VERSION ""

NS_ :

BS_:

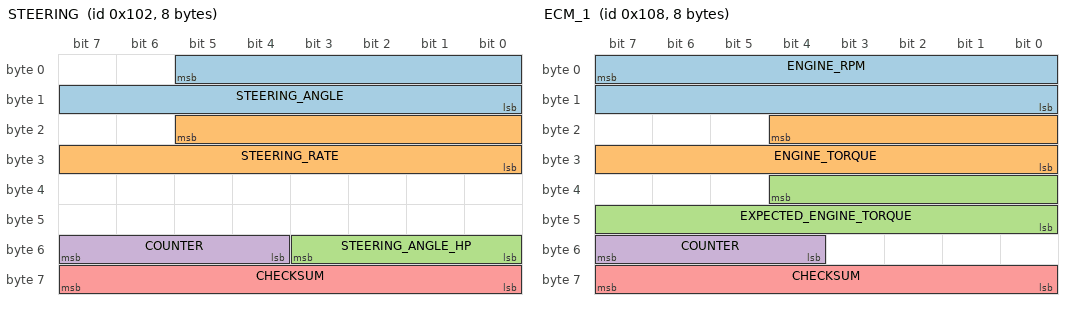
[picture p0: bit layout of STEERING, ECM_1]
BO_ 258 STEERING: 8 XXX
 SG_ STEERING_ANGLE : 5|14@0+ (0.5,-2048) [-2048|2047] "deg" XXX
 SG_ STEERING_RATE : 21|14@0+ (0.5,-2048) [-2048|2047] "deg/s" XXX
 SG_ STEERING_ANGLE_HP : 48|4@1+ (0.1,-0.4) [-0.4|0.4] "deg" XXX
 SG_ COUNTER : 55|4@0+ (1,0) [0|15] "" XXX
 SG_ CHECKSUM : 63|8@0+ (1,0) [0|255] "" XXX

BO_ 264 ECM_1: 8 XXX
 SG_ ENGINE_RPM : 7|16@0+ (1,0) [0|65535] "" XXX
 SG_ ENGINE_TORQUE : 20|13@0+ (0.25,-500) [-500|1547.5] "Nm" XXX
 SG_ EXPECTED_ENGINE_TORQUE : 36|13@0+ (0.25,-500) [-500|1547.5] "Nm" XXX
 SG_ COUNTER : 55|4@0+ (1,0) [0|15] "" XXX
 SG_ CHECKSUM : 63|8@0+ (1,0) [0|255] "" XXX

BO_ 280 ECM_TRQ: 8 XXX
 SG_ ENGINE_TORQ_MAX : 4|13@0+ (.25,-500) [-500|1547.5] "NM" XXX
 SG_ ENGINE_TORQ_MIN : 20|13@0+ (.25,-500) [-500|1547.5] "NM" XXX

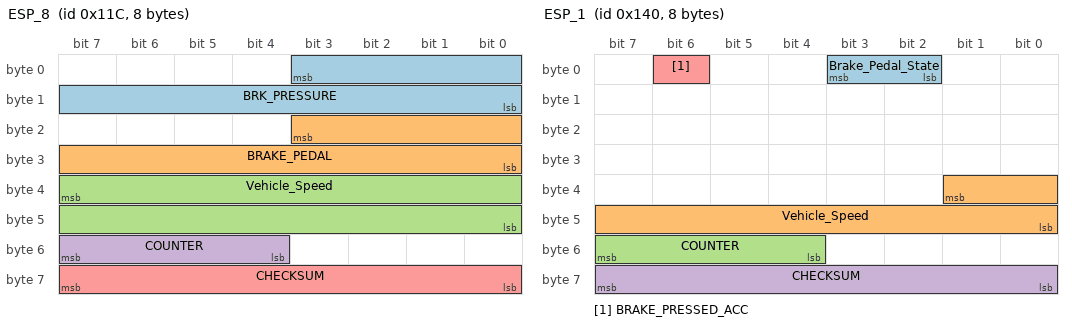
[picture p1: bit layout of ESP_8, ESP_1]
BO_ 284 ESP_8: 8 XXX
 SG_ BRK_PRESSURE : 3|12@0+ (1,0) [0|1] "" XXX
 SG_ BRAKE_PEDAL : 19|12@0+ (1,0) [0|1] "" XXX
 SG_ Vehicle_Speed : 39|16@0+ (0.0078125,0) [0|511.984375] "km/h" XXX
 SG_ COUNTER : 55|4@0+ (1,0) [0|15] "" XXX
 SG_ CHECKSUM : 63|8@0+ (1,0) [0|255] "" XXX

BO_ 320 ESP_1: 8 XXX
 SG_ Brake_Pedal_State : 2|2@1+ (1,0) [0|0] "" XXX
 SG_ Vehicle_Speed : 33|10@0+ (0.5,0) [0|511] "km/h" XXX
 SG_ COUNTER : 55|4@0+ (1,0) [0|15] "" XXX
 SG_ CHECKSUM : 63|8@0+ (1,0) [0|255] "" XXX
 SG_ BRAKE_PRESSED_ACC : 6|1@0+ (1,0) [0|3] "" XXX

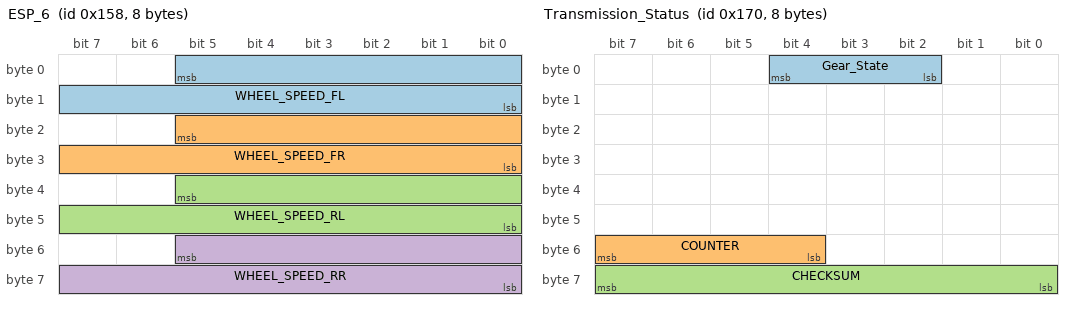
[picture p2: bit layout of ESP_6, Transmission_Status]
BO_ 344 ESP_6: 8 XXX
 SG_ WHEEL_SPEED_FL : 5|14@0+ (0.5,0) [0|8191] "rpm" XXX
 SG_ WHEEL_SPEED_FR : 21|14@0+ (0.5,0) [0|8191] "rpm" XXX
 SG_ WHEEL_SPEED_RL : 37|14@0+ (0.5,0) [0|8191] "rpm" XXX
 SG_ WHEEL_SPEED_RR : 53|14@0+ (0.5,0) [0|8191] "rpm" XXX

BO_ 368 Transmission_Status: 8 XXX
 SG_ Gear_State : 2|3@1+ (1,0) [0|15] "" XXX
 SG_ COUNTER : 55|4@0+ (1,0) [0|15] "" XXX
 SG_ CHECKSUM : 63|8@0+ (1,0) [0|255] "" XXX

BO_ 464 ORC_1: 8 XXX
 SG_ SEATBELT_DRIVER_UNLATCHED : 13|1@0+ (1,0) [0|1] "" XXX

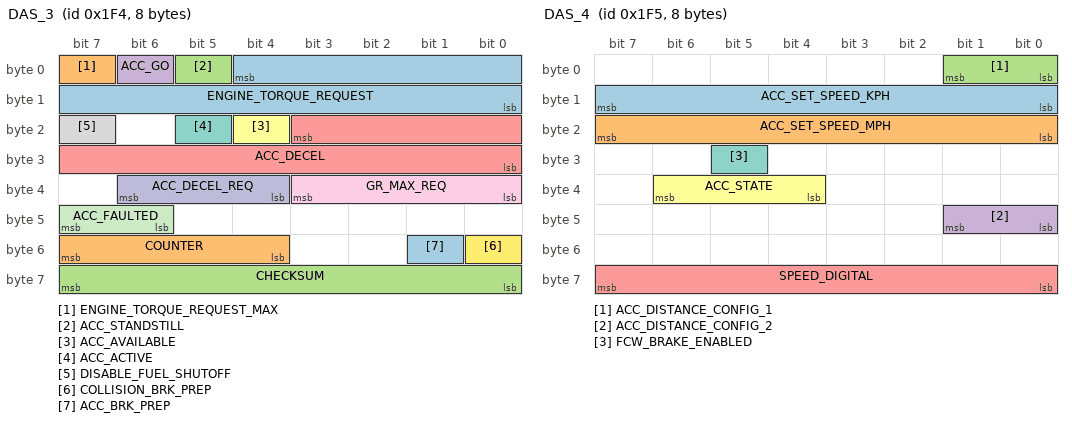
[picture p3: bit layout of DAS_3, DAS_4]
BO_ 500 DAS_3: 8 XXX
 SG_ ENGINE_TORQUE_REQUEST : 4|13@0+ (0.25,-500) [-500|1547.5] "Nm" XXX
 SG_ ENGINE_TORQUE_REQUEST_MAX : 7|1@0+ (1,0) [0|1] "" XXX
 SG_ ACC_STANDSTILL : 5|1@0+ (1,0) [0|1] ""  XXX
 SG_ ACC_GO : 6|1@1+ (1,0) [0|0] "" XXX
 SG_ ACC_DECEL : 19|12@0+ (0.004885,-16) [-16|4] "m/s2" XXX
 SG_ ACC_AVAILABLE : 20|1@0+ (1,0) [0|1] "" XXX
 SG_ ACC_ACTIVE : 21|1@0+ (1,0) [0|1] "" XXX
 SG_ DISABLE_FUEL_SHUTOFF : 23|1@1+ (1,0) [0|0] "" XXX
 SG_ GR_MAX_REQ : 32|4@1+ (1,0) [0|0] "" XXX
 SG_ ACC_DECEL_REQ : 36|3@1+ (1,0) [0|0] "" XXX
 SG_ ACC_FAULTED : 46|2@1+ (1,0) [0|0] "" XXX
 SG_ COLLISION_BRK_PREP : 48|1@1+ (1,0) [0|0] "" XXX
 SG_ ACC_BRK_PREP : 49|1@1+ (1,0) [0|0] "" XXX
 SG_ COUNTER : 55|4@0+ (1,0) [0|15] "" XXX
 SG_ CHECKSUM : 63|8@0+ (1,0) [0|255] "" XXX

BO_ 501 DAS_4: 8 XXX
 SG_ ACC_SET_SPEED_KPH : 15|8@0+ (1,0) [0|3] "km/h" XXX
 SG_ ACC_SET_SPEED_MPH : 23|8@0+ (1,0) [0|3] "mph" XXX
 SG_ ACC_DISTANCE_CONFIG_1 : 1|2@0+ (1,0) [0|3] "" XXX
 SG_ ACC_DISTANCE_CONFIG_2 : 41|2@0+ (1,0) [0|3] "" XXX
 SG_ SPEED_DIGITAL : 63|8@0+ (1,0) [0|255] "mph" XXX
 SG_ ACC_STATE : 38|3@0+ (1,0) [0|7] "" XXX
 SG_ FCW_BRAKE_ENABLED : 29|1@0+ (1,0) [0|1] "" XXX

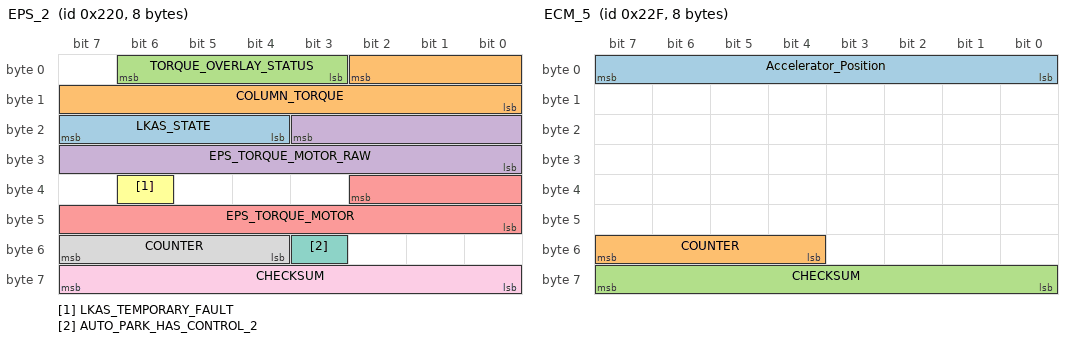
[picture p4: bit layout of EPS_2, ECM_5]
BO_ 544 EPS_2: 8 XXX
 SG_ LKAS_STATE : 23|4@0+ (1,0) [0|15] "" XXX
 SG_ COLUMN_TORQUE : 2|11@0+ (1,-1024) [-1024|1023] "" XXX
 SG_ TORQUE_OVERLAY_STATUS : 6|4@0+ (1,0) [0|15] "" XXX
 SG_ EPS_TORQUE_MOTOR_RAW : 19|12@0+ (1,-2048) [-2048|2047] "" XXX
 SG_ EPS_TORQUE_MOTOR : 34|11@0+ (1,-1024) [-1024|1023] "" XXX
 SG_ LKAS_TEMPORARY_FAULT : 38|1@0+ (1,0) [0|1] "" XXX
 SG_ AUTO_PARK_HAS_CONTROL_2 : 51|1@0+ (1,0) [0|1] "" XXX
 SG_ COUNTER : 55|4@0+ (1,0) [0|15] "" XXX
 SG_ CHECKSUM : 63|8@0+ (1,0) [0|255] "" XXX

BO_ 559 ECM_5: 8 XXX
 SG_ Accelerator_Position : 0|8@1+ (0.4,0) [0|100] "%" XXX
 SG_ COUNTER : 55|4@0+ (1,0) [0|15] "" XXX
 SG_ CHECKSUM : 63|8@0+ (1,0) [0|255] "" XXX

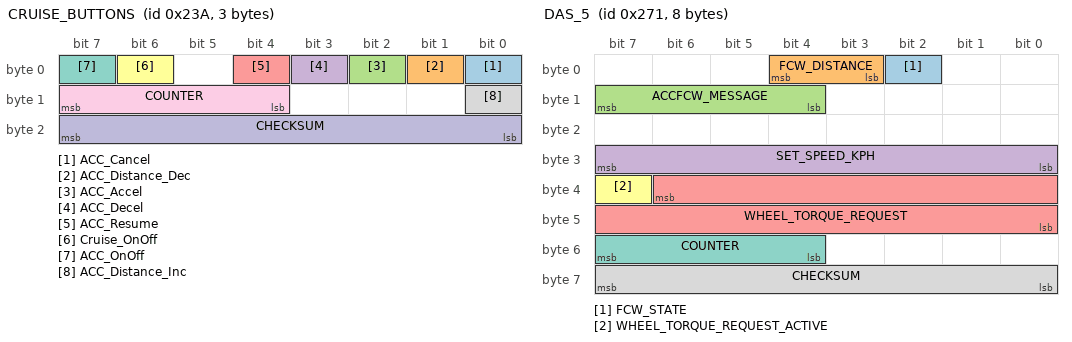
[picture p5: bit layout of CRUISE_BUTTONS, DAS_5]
BO_ 570 CRUISE_BUTTONS: 3 XXX
 SG_ ACC_Cancel : 0|1@1+ (1,0) [0|0] "" XXX
 SG_ ACC_Distance_Dec : 1|1@1+ (1,0) [0|0] "" XXX
 SG_ ACC_Accel : 2|1@1+ (1,0) [0|0] "" XXX
 SG_ ACC_Decel : 3|1@1+ (1,0) [0|0] "" XXX
 SG_ ACC_Resume : 4|1@0+ (1,0) [0|1] "" XXX
 SG_ Cruise_OnOff : 6|1@1+ (1,0) [0|0] "" XXX
 SG_ ACC_OnOff : 7|1@1+ (1,0) [0|0] "" XXX
 SG_ ACC_Distance_Inc : 8|1@1+ (1,0) [0|0] "" XXX
 SG_ COUNTER : 15|4@0+ (1,0) [0|15] "" XXX
 SG_ CHECKSUM : 23|8@0+ (1,0) [0|255] "" XXX

BO_ 625 DAS_5: 8 XXX
 SG_ FCW_STATE : 2|1@1+ (1,0) [0|0] ""  XXX
 SG_ FCW_DISTANCE : 3|2@1+ (1,0) [0|0] ""  XXX
 SG_ ACCFCW_MESSAGE : 12|4@1+ (1,0) [0|0] ""  XXX
 SG_ SET_SPEED_KPH : 24|8@1+ (1,0) [0|250] "km/h"  XXX
 SG_ WHEEL_TORQUE_REQUEST : 38|15@0+ (1,-7767) [-7767|24999] "Nm"  XXX
 SG_ WHEEL_TORQUE_REQUEST_ACTIVE : 39|1@1+ (1,0) [0|0] ""  XXX
 SG_ COUNTER : 55|4@0+ (1,0) [0|15] "" XXX
 SG_ CHECKSUM : 63|8@0+ (1,0) [0|255] "" XXX

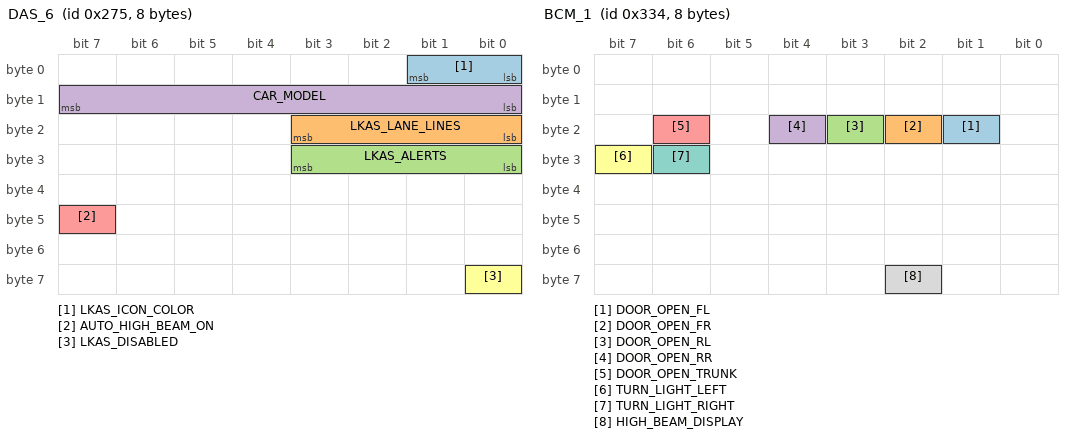
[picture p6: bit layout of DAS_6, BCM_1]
BO_ 629 DAS_6: 8 XXX
 SG_ LKAS_ICON_COLOR : 1|2@0+ (1,0) [0|3] "" XXX
 SG_ LKAS_LANE_LINES : 19|4@0+ (1,0) [0|1] "" XXX
 SG_ LKAS_ALERTS : 27|4@0+ (1,0) [0|1] "" XXX
 SG_ CAR_MODEL : 15|8@0+ (1,0) [0|255] "" XXX
 SG_ AUTO_HIGH_BEAM_ON : 47|1@1+ (1,0) [0|0] "" XXX
 SG_ LKAS_DISABLED : 56|1@1+ (1,0) [0|0] "" XXX

BO_ 720 BSM_1: 6 XXX
 SG_ RIGHT_STATUS : 5|1@0+ (1,0) [0|1] "" XXX
 SG_ LEFT_STATUS : 2|1@0+ (1,0) [0|1] "" XXX

BO_ 792 STEERING_LEVERS: 8 XXX
 SG_ TURN_SIGNALS : 0|2@1+ (1,0) [0|3] "" XXX
 SG_ HIGH_BEAM_PRESSED : 2|1@0+ (1,0) [0|3] "" XXX

BO_ 820 BCM_1: 8 XXX
 SG_ DOOR_OPEN_FL : 17|1@0+ (1,0) [0|1] "" XXX
 SG_ DOOR_OPEN_FR : 18|1@0+ (1,0) [0|1] "" XXX
 SG_ DOOR_OPEN_RL : 19|1@0+ (1,0) [0|1] "" XXX
 SG_ DOOR_OPEN_RR : 20|1@0+ (1,0) [0|1] "" XXX
 SG_ DOOR_OPEN_TRUNK : 22|1@0+ (1,0) [0|1] "" XXX
 SG_ TURN_LIGHT_LEFT : 31|1@0+ (1,0) [0|1] "" XXX
 SG_ TURN_LIGHT_RIGHT : 30|1@0+ (1,0) [0|1] "" XXX
 SG_ HIGH_BEAM_DISPLAY : 58|1@0+ (1,0) [0|1] "" XXX

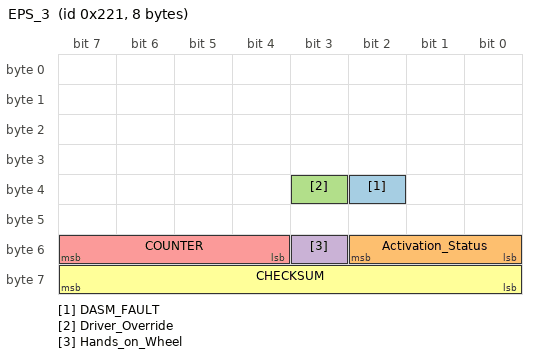
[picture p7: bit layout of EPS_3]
BO_ 545 EPS_3: 8 XXX
 SG_ DASM_FAULT : 34|1@0+ (1,0) [0|1] "" XXX
 SG_ Activation_Status : 48|3@1+ (1,0) [0|1] "" XXX
 SG_ Driver_Override : 35|1@0+ (1,0) [0|1] "" XXX
 SG_ Hands_on_Wheel : 51|1@0+ (1,0) [0|1] "" XXX
 SG_ COUNTER : 55|4@0+ (1,0) [0|15] "" XXX
 SG_ CHECKSUM : 63|8@0+ (1,0) [0|255] "" XXX

CM_ 272 "Alternative LKAS message, used on cars such as 2023 Ioniq 6, 2nd gen Kona. Matches LKAS except size is 32 bytes";
CM_ 676 "Contains signals with detailed lane line information. Used by ADAS ECU on HDA 2 vehicles to operate LFA.";
CM_ 866 "Contains signals with detailed lane line information. Used by ADAS ECU on HDA 2 vehicles to operate LFA. Used on cars that use message 272.";
CM_ 1043 "Lamp signals do not seem universal on cars that use LKAS_ALT, but stalk signals do.";

CM_ SG_ 80 HAS_LANE_SAFETY "If 0, hides LKAS 'Lane Safety' menu from vehicle settings";
CM_ SG_ 96 BRAKE_PRESSURE "User applied brake pedal pressure. Ramps from computer applied pressure on falling edge of cruise. Cruise cancels if !=0";
CM_ SG_ 101 BRAKE_POSITION "User applied brake pedal position, max is ~700. Signed on some vehicles";
CM_ SG_ 373 PROBABLY_EQUIP "aeb equip?";
CM_ SG_ 373 ACCEnable "Likely a copy of CAN's TCS13->ACCEnable";
CM_ SG_ 373 DriverBraking "Likely derived from BRAKE->BRAKE_POSITION";
CM_ SG_ 373 DriverBrakingLowSens "Higher threshold version of DriverBraking";
CM_ SG_ 352 SET_ME_9 "has something to do with AEB settings";
CM_ SG_ 416 VSetDis "set speed in display units";
CM_ SG_ 676 LEFT_LANE_LINE "Left lane line confidence";
CM_ SG_ 676 RIGHT_LANE_LINE "Right lane line confidence";
CM_ SG_ 736 MAX_SPEED "Display units. Restricts car from driving above this speed unless accelerator pedal is depressed beyond pressure point";
CM_ SG_ 866 LEFT_LANE_LINE "Left lane line confidence";
CM_ SG_ 866 RIGHT_LANE_LINE "Right lane line confidence";
CM_ SG_ 961 COUNTER_ALT "only increments on change";
CM_ SG_ 1041 COUNTER_ALT "only increments on change";
CM_ SG_ 1043 COUNTER_ALT "only increments on change";
CM_ SG_ 1043 USE_ALT_LAMP "likely 1 on cars that use alt lamp signals";
VAL_ 513 STATE 5 "FAULT_TIMEOUT" 4 "FAULT_STARTUP" 3 "FAULT_SCE" 2 "FAULT_SEND" 1 "FAULT_BAD_CHECKSUM" 0 "NO_FAULT" ;

VAL_ 295 GEAR 0 "P" 1 "R" 2 "N" 3 "D" 4 "B";
VAL_ 466 CRUISE_STATE 11 "timer_3sec" 10 "adaptive click down" 9 "adaptive click up" 8 "adaptive engaged" 7 "standstill" 6 "non-adaptive click up" 5 "non-adaptive click down" 4 "non-adaptive hold down" 3 "non-adaptive hold up" 2 "non-adaptive being engaged" 1 "non-adaptive engaged" 0 "off";
VAL_ 467 LOW_SPEED_LOCKOUT 2 "low speed locked" 1 "ok";
VAL_ 467 PCM_FOLLOW_DISTANCE 1 "far" 2 "medium" 3 "close";
VAL_ 614 STATE 3 "enabled" 1 "disabled";
VAL_ 614 DIRECTION_CMD 3 "right" 2 "center" 1 "left";
VAL_ 643 STATE 0 "normal" 1 "adaptive_cruise_control" 3 "emergency_braking";
VAL_ 835 ACC_TYPE 2 "permanent low speed lockout" 1 "ok";
VAL_ 835 ACC_MALFUNCTION 1 "faulted" 0 "ok";
VAL_ 835 ACC_CUT_IN 1 "CUT-IN Detected" 0 "clear";
VAL_ 835 ALLOW_LONG_PRESS 2 "set speed increase by 5 speed units regardless" 1 "set speed increase by 1 speed unit on short press, 5 speed units on long press";
VAL_ 865 CLUTCH_RELEASED 0 "clutch pressed any amount" 1 "clutch released"
VAL_ 921 CRUISE_CONTROL_STATE 2 "disabled" 11 "hold" 10 "hold_waiting_user_cmd" 6 "enabled" 5 "faulted";
VAL_ 956 SPORT_ON 0 "off" 1 "on";
VAL_ 956 GEAR 0 "D" 1 "S" 8 "N" 16 "R" 32 "P";
VAL_ 956 SPORT_GEAR_ON 0 "off" 1 "on";
VAL_ 956 SPORT_GEAR 1 "S1" 2 "S2" 3 "S3" 4 "S4" 5 "S5" 6 "S6";
VAL_ 956 ECON_ON 0 "off" 1 "on";
VAL_ 956 B_GEAR_ENGAGED 0 "off" 1 "on";
VAL_ 956 DRIVE_ENGAGED 0 "off" 1 "on";
VAL_ 1005 REVERSE_CAMERA_GUIDELINES 3 "No guidelines" 2 "Static guidelines" 1 "Active guidelines";
VAL_ 1009 PCM_FOLLOW_DISTANCE 1 "far" 2 "medium" 3 "close";
VAL_ 1041 PCS_INDICATOR 2 "PCS Faulted" 1 "PCS Turned Off By User" 0 "PCS Enabled";
VAL_ 1041 PCS_SENSITIVITY 64 "high sensitivity"  128 "mid sensitivity" 192 "low sensitivity" 0 "off";
VAL_ 1042 LDA_ALERT 3 "hold with continuous beep" 2 "LDA unavailable" 1 "hold" 0 "none";
VAL_ 1042 BARRIERS 3 "left" 2 "right" 1 "both" 0 "none";
VAL_ 1042 RIGHT_LINE 3 "orange" 2 "faded" 1 "solid" 0 "none";
VAL_ 1042 LKAS_STATUS 1 "on" 0 "off";
VAL_ 1042 LEFT_LINE 3 "orange" 2 "faded" 1 "solid" 0 "none";
VAL_ 1042 LDA_ON_MESSAGE 2 "Lane Departure Alert Turned ON, Steering Assist Inactive" 1 "Lane Departure Alert Turned ON, Steering Assist Active" 0 "clear";
VAL_ 1042 LDA_SA_TOGGLE  2 "steering assist off" 1 "steering assist on";
VAL_ 1042 LDA_SENSITIVITY 2 "standard" 1 "high" 0 "undefined";
VAL_ 1042 LDA_MESSAGES 4 "lda unavailable at this speed" 1 "lda unavailable below approx 50km/h" 0 "ok";
VAL_ 1042 LDA_FRONT_CAMERA_BLOCKED 1 "lda unavailable" 0 "ok";
VAL_ 1042 TAKE_CONTROL 1 "take control" 0 "ok";
VAL_ 1042 LANE_SWAY_WARNING 3 "ok" 2 "orange please take a break" 1 "prompt would you like to take a break" 0 "ok";
VAL_ 1042 LANE_SWAY_BUZZER 3 "ok" 2 "beep twice" 1 "beep twice" 0 "ok";
VAL_ 1161 TSGN1 1 "speed sign" 0 "none";
VAL_ 1161 TSGN2 1 "speed sign" 0 "none";
VAL_ 1161 SPLSGN2 15 "conditional blank" 4 "wet road" 5 "rain" 0 "none";
VAL_ 1162 TSGN3 0 "none" 1 "speed sign" 2 "0 unlimited" 7 "unlimited" 16 "highway" 17 "no highway" 18 "motorway" 19 "no motorway" 20 "in city" 21 "outside city" 22 "pedestrian area" 23 "no pedestrian area" 65 "no overtaking left" 66 "no overtaking right" 67 "overtaking allowed again" 81 "no right turn" 97 "stop" 105 "yield" 113 "stop" 114 "yield us" 129 "no entry" 138 "no entry tss2" 145 "do not enter";
VAL_ 1162 SPLSGN3 15 "conditional blank" 4 "wet road" 5 "rain" 0 "none";
VAL_ 1552 METER_SLIDER_LOW_BRIGHTNESS 1 "Low brightness mode, footwell lights off" 0 "Normal mode, footwell lights on";
VAL_ 1552 METER_SLIDER_DIMMED 1 "Dimmed" 0 "Not Dimmed";
VAL_ 1552 UNITS 1 "km (km/L)" 2 "km (L/100km)" 3 "miles (MPG US)" 4 "miles (MPG Imperial)";
VAL_ 1553 UNITS 1 "km" 2 "miles";
VAL_ 1556 TURN_SIGNALS 3 "none" 2 "right" 1 "left";
VAL_ 1592 LOCK_STATUS 0 "locked" 1 "unlocked";

VAL_ 610 IPAS_STATE 5 "override" 3 "enabled" 1 "disabled";
